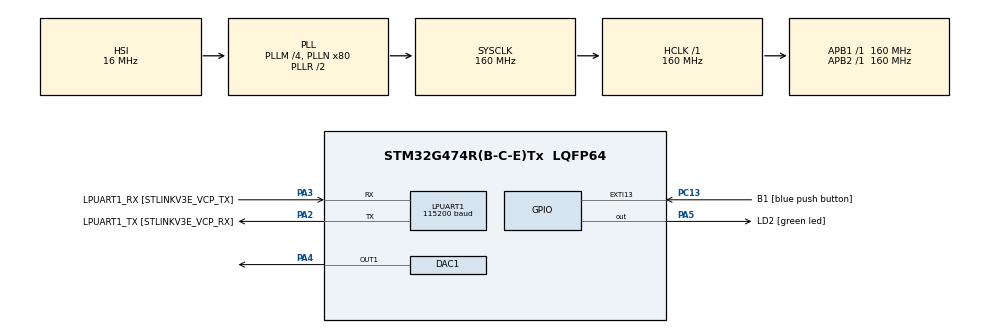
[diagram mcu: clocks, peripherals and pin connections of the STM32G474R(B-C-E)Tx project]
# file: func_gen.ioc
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DAC1.DAC_HighFrequency_OUT1-DAC_OUT1=DAC_HIGH_FREQUENCY_INTERFACE_MODE_ABOVE_80MHZ
DAC1.DAC_Trigger2_OUT1-DAC_OUT1=DAC_TRIGGER_T6_TRGO
DAC1.DAC_Trigger_OUT1-DAC_OUT1=DAC_TRIGGER_T2_TRGO
DAC1.WaveGeneration_OUT1-DAC_OUT1=DISABLE
Dma.DAC1_CH1.0.Direction=DMA_MEMORY_TO_PERIPH
Dma.DAC1_CH1.0.EventEnable=DISABLE
Dma.DAC1_CH1.0.Instance=DMA1_Channel1
Dma.DAC1_CH1.0.MemDataAlignment=DMA_MDATAALIGN_HALFWORD
Dma.DAC1_CH1.0.MemInc=DMA_MINC_ENABLE
Dma.DAC1_CH1.0.Mode=DMA_CIRCULAR
Dma.DAC1_CH1.0.PeriphDataAlignment=DMA_PDATAALIGN_WORD
Dma.DAC1_CH1.0.PeriphInc=DMA_PINC_DISABLE
Dma.DAC1_CH1.0.Polarity=HAL_DMAMUX_REQ_GEN_RISING
Dma.DAC1_CH1.0.Priority=DMA_PRIORITY_LOW
Dma.DAC1_CH1.0.RequestNumber=1
Dma.DAC1_CH1.0.SignalID=NONE
Dma.DAC1_CH1.0.SyncEnable=DISABLE
Dma.DAC1_CH1.0.SyncPolarity=HAL_DMAMUX_SYNC_NO_EVENT
Dma.DAC1_CH1.0.SyncRequestNumber=1
Dma.DAC1_CH1.0.SyncSignalID=NONE
Dma.Request0=DAC1_CH1
FREERTOS.Tasks01=defaultTask,8,128,StartDefaultTask,Default,NULL,Dynamic,NULL,NULL;taskUartRx,40,256,startUartRx,Default,NULL,Dynamic,NULL,NULL;taskFuncGen,24,256,startFuncGen,Default,NULL,Dynamic,NULL,NULL
FREERTOS.configENABLE_FPU=0
FREERTOS.configTICK_RATE_HZ=1000
FREERTOS.configTOTAL_HEAP_SIZE=3072
LPUART1.BaudRate=115200
LPUART1.WordLength=UART_WORDLENGTH_8B
Mcu.Family=STM32G4
Mcu.Name=STM32G474R(B-C-E)Tx
Mcu.Package=LQFP64
NVIC.DMA1_Channel1_IRQn=true\:5\:0\:false\:false\:true\:true\:false\:true
NVIC.EXTI15_10_IRQn=true\:5\:0\:false\:false\:true\:false\:true\:true
NVIC.LPUART1_IRQn=true\:5\:0\:true\:false\:true\:false\:true\:true
NVIC.PriorityGroup=NVIC_PRIORITYGROUP_4
NVIC.TIM1_UP_TIM16_IRQn=true\:0\:0\:false\:false\:true\:false\:false\:true
NVIC.TimeBase=TIM1_UP_TIM16_IRQn
NVIC.TimeBaseIP=TIM1
PA13.GPIO_Label=T_SWDIO
PA13.Mode=Serial_Wire
PA13.Signal=SYS_JTMS-SWDIO
PA14.GPIO_Label=T_SWCLK
PA14.Mode=Serial_Wire
PA14.Signal=SYS_JTCK-SWCLK
PA2.GPIO_Label=LPUART1_TX [STLINKV3E_VCP_RX]
PA2.Mode=Asynchronous
PA2.Signal=LPUART1_TX
PA3.GPIO_Label=LPUART1_RX [STLINKV3E_VCP_TX]
PA3.Mode=Asynchronous
PA3.Signal=LPUART1_RX
PA4.Signal=COMP_DAC11_group
PA5.GPIO_Label=LD2 [green led]
PA5.Signal=GPIO_Output
PB3.GPIO_Label=T_SWO
PB3.Signal=SYS_JTDO-SWO
PC13.GPIO_Label=B1 [blue push button]
PC13.Signal=GPXTI13
PC14-OSC32_IN.Mode=LSE-External-Oscillator
PC14-OSC32_IN.Signal=RCC_OSC32_IN
PC15-OSC32_OUT.Mode=LSE-External-Oscillator
PC15-OSC32_OUT.Signal=RCC_OSC32_OUT
PF0-OSC_IN.Mode=HSE-External-Oscillator
PF0-OSC_IN.Signal=RCC_OSC_IN
PF1-OSC_OUT.Mode=HSE-External-Oscillator
PF1-OSC_OUT.Signal=RCC_OSC_OUT
ProjectManager.HeapSize=0x200
ProjectManager.StackSize=0x400
ProjectManager.TargetToolchain=STM32CubeIDE
RCC.ADC12Freq_Value=160000000
RCC.ADC345Freq_Value=160000000
RCC.AHBFreq_Value=160000000
RCC.APB1Freq_Value=160000000
RCC.APB1TimFreq_Value=160000000
RCC.APB2Freq_Value=160000000
RCC.APB2TimFreq_Value=160000000
RCC.CortexFreq_Value=160000000
RCC.EXTERNAL_CLOCK_VALUE=12288000
RCC.HCLKFreq_Value=160000000
RCC.HSE_VALUE=24000000
RCC.HSI48_VALUE=48000000
RCC.HSI_VALUE=16000000
RCC.PLLM=RCC_PLLM_DIV4
RCC.PLLN=80
RCC.RTCClockSelection=RCC_RTCCLKSOURCE_LSE
RCC.SYSCLKFreq_VALUE=160000000
RCC.SYSCLKSource=RCC_SYSCLKSOURCE_PLLCLK
RCC.USBFreq_Value=160000000
RCC.VCOOutputFreq_Value=320000000
SH.COMP_DAC11_group.0=DAC1_OUT1,DAC_OUT1
TIM2.PeriodNoDither=1
TIM2.Prescaler=0
TIM2.TIM_MasterOutputTrigger=TIM_TRGO_UPDATE
VP_FREERTOS_VS_CMSIS_V2.Mode=CMSIS_V2
VP_SYS_VS_DBSignals.Mode=DisableDeadBatterySignals
VP_SYS_VS_tim1.Mode=TIM1
VP_TIM2_VS_ClockSourceINT.Mode=Internal
board=NUCLEO-G474RE

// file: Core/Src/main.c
/* USER CODE BEGIN Header */
/**
 ******************************************************************************
 * @file           : main.c
 * @brief          : Main program body
 ******************************************************************************
 * @attention
 *
 * <h2><center>&copy; Copyright (c) 2020 STMicroelectronics.
 * All rights reserved.</center></h2>
 *
 * This software component is licensed by ST under BSD 3-Clause license,
 * the "License"; You may not use this file except in compliance with the
 * License. You may obtain a copy of the License at:
 *                        opensource.org/licenses/BSD-3-Clause
 *
 ******************************************************************************
 */
/* USER CODE END Header */
#include "main.h"
#include "cmsis_os.h"

/* USER CODE BEGIN Includes */
#include <string.h>
#include "app_funcGen.h"
#include "app_uartTx.h"
#include "app_uartRx.h"
#include "app_log.h"
/* USER CODE END Includes */

DAC_HandleTypeDef hdac1;
DMA_HandleTypeDef hdma_dac1_ch1;

TIM_HandleTypeDef htim2;

/* Definitions for defaultTask */
osThreadId_t defaultTaskHandle;
const osThreadAttr_t defaultTask_attributes = {
  .name = "defaultTask",
  .priority = (osPriority_t) osPriorityLow,
  .stack_size = 128 * 4
};
/* Definitions for taskUartRx */
osThreadId_t taskUartRxHandle;
const osThreadAttr_t taskUartRx_attributes = {
  .name = "taskUartRx",
  .priority = (osPriority_t) osPriorityHigh,
  .stack_size = 256 * 4
};
/* Definitions for taskFuncGen */
osThreadId_t taskFuncGenHandle;
const osThreadAttr_t taskFuncGen_attributes = {
  .name = "taskFuncGen",
  .priority = (osPriority_t) osPriorityNormal,
  .stack_size = 256 * 4
};

void SystemClock_Config(void);
static void MX_GPIO_Init(void);
static void MX_DMA_Init(void);
static void MX_LPUART1_UART_Init(void);
static void MX_DAC1_Init(void);
static void MX_TIM2_Init(void);
void StartDefaultTask(void *argument);
void startUartRx(void *argument);
void startFuncGen(void *argument);

int main(void)
{

  /* MCU Configuration--------------------------------------------------------*/

  /* Reset of all peripherals, Initializes the Flash interface and the Systick. */
  HAL_Init();

  /* Configure the system clock */
  SystemClock_Config();

  /* Initialize all configured peripherals */
  MX_GPIO_Init();
  MX_DMA_Init();
  MX_LPUART1_UART_Init();
  MX_DAC1_Init();
  MX_TIM2_Init();
  /* USER CODE BEGIN 2 */
  log_init(HAL_GetTick, uartPrint);
  log_debug("Drivers initialized and program started");

  /* USER CODE END 2 */

  /* Init scheduler */
  osKernelInitialize();

  /* Create the thread(s) */
  /* creation of defaultTask */
  defaultTaskHandle = osThreadNew(StartDefaultTask, NULL, &defaultTask_attributes);

  /* creation of taskUartRx */
  taskUartRxHandle = osThreadNew(startUartRx, NULL, &taskUartRx_attributes);

  /* creation of taskFuncGen */
  taskFuncGenHandle = osThreadNew(startFuncGen, NULL, &taskFuncGen_attributes);

  /* Start scheduler */
  osKernelStart();

  /* We should never get here as control is now taken by the scheduler */
  /* Infinite loop */
	while (1)
	{

	}
}

void SystemClock_Config(void)
{
  RCC_OscInitTypeDef RCC_OscInitStruct = {0};
  RCC_ClkInitTypeDef RCC_ClkInitStruct = {0};
  RCC_PeriphCLKInitTypeDef PeriphClkInit = {0};

  /** Configure the main internal regulator output voltage
  */
  HAL_PWREx_ControlVoltageScaling(PWR_REGULATOR_VOLTAGE_SCALE1_BOOST);
  /** Initializes the RCC Oscillators according to the specified parameters
  * in the RCC_OscInitTypeDef structure.
  */
  RCC_OscInitStruct.OscillatorType = RCC_OSCILLATORTYPE_HSI;
  RCC_OscInitStruct.HSIState = RCC_HSI_ON;
  RCC_OscInitStruct.HSICalibrationValue = RCC_HSICALIBRATION_DEFAULT;
  RCC_OscInitStruct.PLL.PLLState = RCC_PLL_ON;
  RCC_OscInitStruct.PLL.PLLSource = RCC_PLLSOURCE_HSI;
  RCC_OscInitStruct.PLL.PLLM = RCC_PLLM_DIV4;
  RCC_OscInitStruct.PLL.PLLN = 80;
  RCC_OscInitStruct.PLL.PLLP = RCC_PLLP_DIV2;
  RCC_OscInitStruct.PLL.PLLQ = RCC_PLLQ_DIV2;
  RCC_OscInitStruct.PLL.PLLR = RCC_PLLR_DIV2;
  if (HAL_RCC_OscConfig(&RCC_OscInitStruct) != HAL_OK)
  {
    Error_Handler();
  }
  /** Initializes the CPU, AHB and APB buses clocks
  */
  RCC_ClkInitStruct.ClockType = RCC_CLOCKTYPE_HCLK|RCC_CLOCKTYPE_SYSCLK
                              |RCC_CLOCKTYPE_PCLK1|RCC_CLOCKTYPE_PCLK2;
  RCC_ClkInitStruct.SYSCLKSource = RCC_SYSCLKSOURCE_PLLCLK;
  RCC_ClkInitStruct.AHBCLKDivider = RCC_SYSCLK_DIV1;
  RCC_ClkInitStruct.APB1CLKDivider = RCC_HCLK_DIV1;
  RCC_ClkInitStruct.APB2CLKDivider = RCC_HCLK_DIV1;

  if (HAL_RCC_ClockConfig(&RCC_ClkInitStruct, FLASH_LATENCY_4) != HAL_OK)
  {
    Error_Handler();
  }
  /** Initializes the peripherals clocks
  */
  PeriphClkInit.PeriphClockSelection = RCC_PERIPHCLK_LPUART1;
  PeriphClkInit.Lpuart1ClockSelection = RCC_LPUART1CLKSOURCE_PCLK1;
  if (HAL_RCCEx_PeriphCLKConfig(&PeriphClkInit) != HAL_OK)
  {
    Error_Handler();
  }
}

static void MX_DAC1_Init(void)
{

  DAC_ChannelConfTypeDef sConfig = {0};

  /** DAC Initialization
  */
  hdac1.Instance = DAC1;
  if (HAL_DAC_Init(&hdac1) != HAL_OK)
  {
    Error_Handler();
  }
  /** DAC channel OUT1 config
  */
  sConfig.DAC_HighFrequency = DAC_HIGH_FREQUENCY_INTERFACE_MODE_ABOVE_80MHZ;
  sConfig.DAC_DMADoubleDataMode = DISABLE;
  sConfig.DAC_SignedFormat = DISABLE;
  sConfig.DAC_SampleAndHold = DAC_SAMPLEANDHOLD_DISABLE;
  sConfig.DAC_Trigger = DAC_TRIGGER_T2_TRGO;
  sConfig.DAC_Trigger2 = DAC_TRIGGER_T6_TRGO;
  sConfig.DAC_OutputBuffer = DAC_OUTPUTBUFFER_ENABLE;
  sConfig.DAC_ConnectOnChipPeripheral = DAC_CHIPCONNECT_EXTERNAL;
  sConfig.DAC_UserTrimming = DAC_TRIMMING_FACTORY;
  if (HAL_DAC_ConfigChannel(&hdac1, &sConfig, DAC_CHANNEL_1) != HAL_OK)
  {
    Error_Handler();
  }

}

static void MX_LPUART1_UART_Init(void)
{

  LL_LPUART_InitTypeDef LPUART_InitStruct = {0};

  LL_GPIO_InitTypeDef GPIO_InitStruct = {0};

  /* Peripheral clock enable */
  LL_APB1_GRP2_EnableClock(LL_APB1_GRP2_PERIPH_LPUART1);

  LL_AHB2_GRP1_EnableClock(LL_AHB2_GRP1_PERIPH_GPIOA);
  /**LPUART1 GPIO Configuration
  PA2   ------> LPUART1_TX
  PA3   ------> LPUART1_RX
  */
  GPIO_InitStruct.Pin = LL_GPIO_PIN_2;
  GPIO_InitStruct.Mode = LL_GPIO_MODE_ALTERNATE;
  GPIO_InitStruct.Speed = LL_GPIO_SPEED_FREQ_LOW;
  GPIO_InitStruct.OutputType = LL_GPIO_OUTPUT_PUSHPULL;
  GPIO_InitStruct.Pull = LL_GPIO_PULL_NO;
  GPIO_InitStruct.Alternate = LL_GPIO_AF_12;
  LL_GPIO_Init(GPIOA, &GPIO_InitStruct);

  GPIO_InitStruct.Pin = LL_GPIO_PIN_3;
  GPIO_InitStruct.Mode = LL_GPIO_MODE_ALTERNATE;
  GPIO_InitStruct.Speed = LL_GPIO_SPEED_FREQ_LOW;
  GPIO_InitStruct.OutputType = LL_GPIO_OUTPUT_PUSHPULL;
  GPIO_InitStruct.Pull = LL_GPIO_PULL_NO;
  GPIO_InitStruct.Alternate = LL_GPIO_AF_12;
  LL_GPIO_Init(GPIOA, &GPIO_InitStruct);

  /* LPUART1 interrupt Init */
  NVIC_SetPriority(LPUART1_IRQn, NVIC_EncodePriority(NVIC_GetPriorityGrouping(),5, 0));
  NVIC_EnableIRQ(LPUART1_IRQn);

  LPUART_InitStruct.PrescalerValue = LL_LPUART_PRESCALER_DIV1;
  LPUART_InitStruct.BaudRate = 115200;
  LPUART_InitStruct.DataWidth = LL_LPUART_DATAWIDTH_8B;
  LPUART_InitStruct.StopBits = LL_LPUART_STOPBITS_1;
  LPUART_InitStruct.Parity = LL_LPUART_PARITY_NONE;
  LPUART_InitStruct.TransferDirection = LL_LPUART_DIRECTION_TX_RX;
  LPUART_InitStruct.HardwareFlowControl = LL_LPUART_HWCONTROL_NONE;
  LL_LPUART_Init(LPUART1, &LPUART_InitStruct);
  LL_LPUART_SetTXFIFOThreshold(LPUART1, LL_LPUART_FIFOTHRESHOLD_1_8);
  LL_LPUART_SetRXFIFOThreshold(LPUART1, LL_LPUART_FIFOTHRESHOLD_1_8);
  LL_LPUART_DisableFIFO(LPUART1);

  LL_LPUART_Enable(LPUART1);

  /* Polling LPUART1 initialisation */
  while((!(LL_LPUART_IsActiveFlag_TEACK(LPUART1))) || (!(LL_LPUART_IsActiveFlag_REACK(LPUART1))))
  {
  }

}

static void MX_TIM2_Init(void)
{

  TIM_ClockConfigTypeDef sClockSourceConfig = {0};
  TIM_MasterConfigTypeDef sMasterConfig = {0};

  htim2.Instance = TIM2;
  htim2.Init.Prescaler = 0;
  htim2.Init.CounterMode = TIM_COUNTERMODE_UP;
  htim2.Init.Period = 1;
  htim2.Init.ClockDivision = TIM_CLOCKDIVISION_DIV1;
  htim2.Init.AutoReloadPreload = TIM_AUTORELOAD_PRELOAD_DISABLE;
  if (HAL_TIM_Base_Init(&htim2) != HAL_OK)
  {
    Error_Handler();
  }
  sClockSourceConfig.ClockSource = TIM_CLOCKSOURCE_INTERNAL;
  if (HAL_TIM_ConfigClockSource(&htim2, &sClockSourceConfig) != HAL_OK)
  {
    Error_Handler();
  }
  sMasterConfig.MasterOutputTrigger = TIM_TRGO_UPDATE;
  sMasterConfig.MasterSlaveMode = TIM_MASTERSLAVEMODE_DISABLE;
  if (HAL_TIMEx_MasterConfigSynchronization(&htim2, &sMasterConfig) != HAL_OK)
  {
    Error_Handler();
  }

}

static void MX_DMA_Init(void)
{

  /* DMA controller clock enable */
  __HAL_RCC_DMAMUX1_CLK_ENABLE();
  __HAL_RCC_DMA1_CLK_ENABLE();

  /* DMA interrupt init */
  /* DMA1_Channel1_IRQn interrupt configuration */
  HAL_NVIC_SetPriority(DMA1_Channel1_IRQn, 5, 0);
  HAL_NVIC_EnableIRQ(DMA1_Channel1_IRQn);

}

static void MX_GPIO_Init(void)
{
  GPIO_InitTypeDef GPIO_InitStruct = {0};

  /* GPIO Ports Clock Enable */
  __HAL_RCC_GPIOC_CLK_ENABLE();
  __HAL_RCC_GPIOF_CLK_ENABLE();
  __HAL_RCC_GPIOA_CLK_ENABLE();
  __HAL_RCC_GPIOB_CLK_ENABLE();

  /*Configure GPIO pin Output Level */
  HAL_GPIO_WritePin(LD2_GPIO_Port, LD2_Pin, GPIO_PIN_RESET);

  /*Configure GPIO pin : B1_Pin */
  GPIO_InitStruct.Pin = B1_Pin;
  GPIO_InitStruct.Mode = GPIO_MODE_IT_RISING;
  GPIO_InitStruct.Pull = GPIO_NOPULL;
  HAL_GPIO_Init(B1_GPIO_Port, &GPIO_InitStruct);

  /*Configure GPIO pin : LD2_Pin */
  GPIO_InitStruct.Pin = LD2_Pin;
  GPIO_InitStruct.Mode = GPIO_MODE_OUTPUT_PP;
  GPIO_InitStruct.Pull = GPIO_NOPULL;
  GPIO_InitStruct.Speed = GPIO_SPEED_FREQ_LOW;
  HAL_GPIO_Init(LD2_GPIO_Port, &GPIO_InitStruct);

  /* EXTI interrupt init*/
  HAL_NVIC_SetPriority(EXTI15_10_IRQn, 5, 0);
  HAL_NVIC_EnableIRQ(EXTI15_10_IRQn);

}

void StartDefaultTask(void *argument)
{
	for(;;)
	{
		osDelay(1);
	}
}

void startUartRx(void *argument)
{
  /* USER CODE BEGIN startUartRx */
	processUartRx();
  /* USER CODE END startUartRx */
}

void startFuncGen(void *argument)
{
  /* USER CODE BEGIN startFuncGen */
	processNewSignal(&htim2, &hdac1);
  /* USER CODE END startFuncGen */
}

 /**
  * @brief  Period elapsed callback in non blocking mode
  * @note   This function is called  when TIM1 interrupt took place, inside
  * HAL_TIM_IRQHandler(). It makes a direct call to HAL_IncTick() to increment
  * a global variable "uwTick" used as application time base.
  * @param  htim : TIM handle
  * @retval None
  */
void HAL_TIM_PeriodElapsedCallback(TIM_HandleTypeDef *htim)
{
  if (htim->Instance == TIM1) {
    HAL_IncTick();
  }
}

void Error_Handler(void)
{
  /* USER CODE BEGIN Error_Handler_Debug */
	/* User can add his own implementation to report the HAL error return state */
	while(1);
  /* USER CODE END Error_Handler_Debug */
}

/************************ (C) COPYRIGHT STMicroelectronics *****END OF FILE****/
